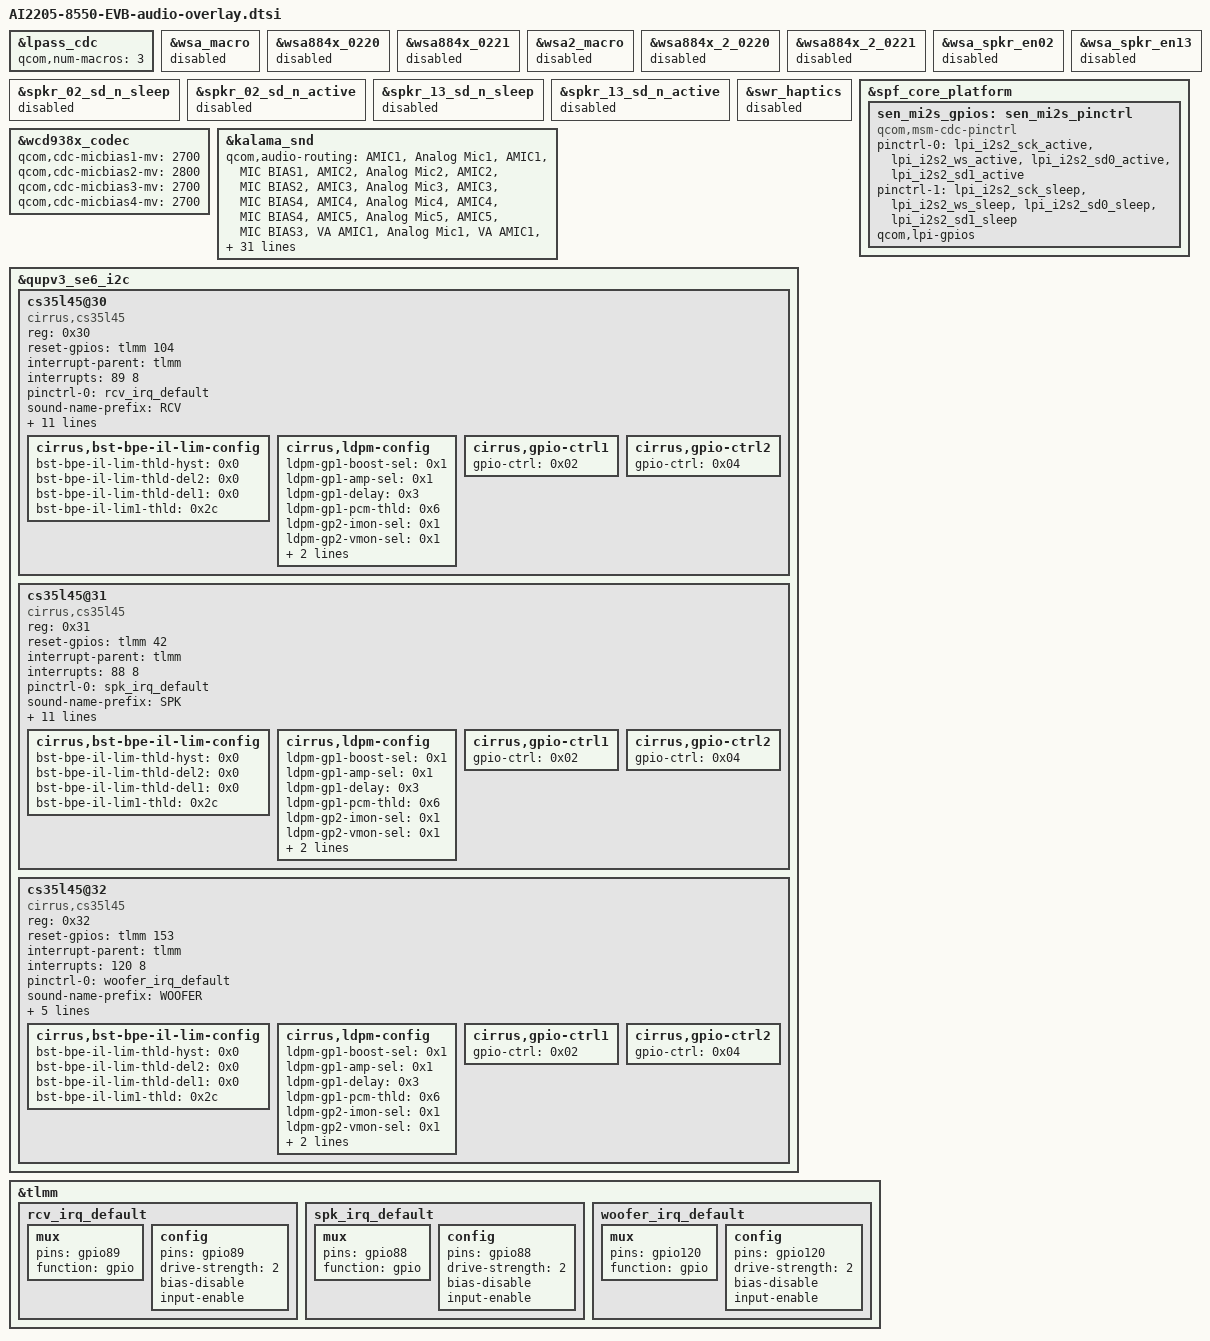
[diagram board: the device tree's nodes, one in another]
#include "kalama-audio-overlay.dtsi"

&lpass_cdc {
	qcom,num-macros = <3>;
};

&wsa_macro {
	status = "disabled";
};

&wsa884x_0220 {
	status = "disabled";
};

&wsa884x_0221 {
	status = "disabled";
};

&wsa2_macro {
	status = "disabled";
};

&wsa884x_2_0220 {
	status = "disabled";
};

&wsa884x_2_0221 {
	status = "disabled";
};

&wsa_spkr_en02 {
	status = "disabled";
};

&wsa_spkr_en13 {
	status = "disabled";
};

&spkr_02_sd_n_sleep {
	status = "disabled";
};

&spkr_02_sd_n_active {
	status = "disabled";
};

&spkr_13_sd_n_sleep {
	status = "disabled";
};

&spkr_13_sd_n_active {
	status = "disabled";
};

&swr_haptics {
	status = "disabled";
};

&spf_core_platform {
	sen_mi2s_gpios: sen_mi2s_pinctrl {
		compatible = "qcom,msm-cdc-pinctrl";
		pinctrl-names = "aud_active", "aud_sleep";
		pinctrl-0 = <&lpi_i2s2_sck_active &lpi_i2s2_ws_active
				&lpi_i2s2_sd0_active &lpi_i2s2_sd1_active>;
		pinctrl-1 = <&lpi_i2s2_sck_sleep &lpi_i2s2_ws_sleep
				&lpi_i2s2_sd0_sleep &lpi_i2s2_sd1_sleep>;
		qcom,lpi-gpios;
		#gpio-cells = <0>;
	};
};

&sen_mi2s_gpios {
	status = "ok";
};

&wcd938x_codec {
	qcom,cdc-micbias1-mv = <2700>;
	qcom,cdc-micbias2-mv = <2800>;
	qcom,cdc-micbias3-mv = <2700>;
	qcom,cdc-micbias4-mv = <2700>;
};

&kalama_snd {
	qcom,audio-routing =
		"AMIC1", "Analog Mic1",
		"AMIC1", "MIC BIAS1",
		"AMIC2", "Analog Mic2",
		"AMIC2", "MIC BIAS2",
		"AMIC3", "Analog Mic3",
		"AMIC3", "MIC BIAS4",
		"AMIC4", "Analog Mic4",
		"AMIC4", "MIC BIAS4",
		"AMIC5", "Analog Mic5",
		"AMIC5", "MIC BIAS3",
		"VA AMIC1", "Analog Mic1",
		"VA AMIC1", "VA MIC BIAS1",
		"VA AMIC2", "Analog Mic2",
		"VA AMIC2", "VA MIC BIAS2",
		"VA AMIC3", "Analog Mic3",
		"VA AMIC3", "VA MIC BIAS3",
		"VA AMIC4", "Analog Mic4",
		"VA AMIC4", "VA MIC BIAS3",
		"VA AMIC5", "Analog Mic5",
		"VA AMIC5", "VA MIC BIAS4",
		"TX DMIC0", "Digital Mic0",
		"TX DMIC0", "MIC BIAS3",
		"TX DMIC1", "Digital Mic1",
		"TX DMIC1", "MIC BIAS3",
		"TX DMIC2", "Digital Mic2",
		"TX DMIC2", "MIC BIAS1",
		"TX DMIC3", "Digital Mic3",
		"TX DMIC3", "MIC BIAS1",
		"IN1_HPHL", "HPHL_OUT",
		"IN2_HPHR", "HPHR_OUT",
		"IN3_AUX", "AUX_OUT",
		"RX_TX DEC0_INP", "TX DEC0 MUX",
		"RX_TX DEC1_INP", "TX DEC1 MUX",
		"RX_TX DEC2_INP", "TX DEC2 MUX",
		"RX_TX DEC3_INP", "TX DEC3 MUX",
		"TX SWR_INPUT", "WCD_TX_OUTPUT",
		"VA SWR_INPUT", "VA_SWR_CLK",
		"VA SWR_INPUT", "WCD_TX_OUTPUT",
		"VA_AIF1 CAP", "VA_SWR_CLK",
		"VA_AIF2 CAP", "VA_SWR_CLK",
		"VA_AIF3 CAP", "VA_SWR_CLK",
		"VA DMIC0", "Digital Mic0",
		"VA DMIC1", "Digital Mic1",
		"VA DMIC2", "Digital Mic2",
		"VA DMIC3", "Digital Mic3",
		"VA DMIC0", "VA MIC BIAS3",
		"VA DMIC1", "VA MIC BIAS3",
		"VA DMIC2", "VA MIC BIAS1",
		"VA DMIC3", "VA MIC BIAS1";

	asoc-codec  = <&stub_codec>, <&lpass_cdc>,
		      <&wcd938x_codec>;
	asoc-codec-names = "msm-stub-codec.1", "lpass-cdc",
			   "wcd938x_codec";
	qcom,wsa-max-devs = <0>;

	qcom,mi2s-audio-intf = <1>;
	qcom,sen-mi2s-gpios = <&sen_mi2s_gpios>;
};

&qupv3_se6_i2c {
	status = "ok";

	cs35l45@30 {
		status = "ok";
		compatible = "cirrus,cs35l45";
		reg = <0x30>;
		reset-gpios = <&tlmm 104 0>;
		interrupt-parent = <&tlmm>;
		interrupts = <89 8>;
		pinctrl-names = "default";
		pinctrl-0 = <&rcv_irq_default>;

		sound-name-prefix = "RCV";
		cirrus,dsp-part-name = "cs35l45-rcv";
		cirrus,fast-switch = "cs35l45-rcv-music.txt",
					"cs35l45-rcv-heavy.txt",
					"cs35l45-rcv-outdoor.txt",
					"cs35l45-rcv-voice.txt",
					"cs35l45-rcv-interim-woofer.txt",
					"cs35l45-rcv-music_woofer_2p1.txt",
					"cs35l45-rcv-heavy_woofer_2p1.txt",
					"cs35l45-rcv-outdoor_woofer_2p1.txt",
					"cs35l45-rcv-voice_woofer_2p1.txt";

		cirrus,asp-sdout-hiz-ctrl = <0x3>;
		cirrus,bst-bpe-il-lim-config {
			bst-bpe-il-lim-thld-hyst = <0x0>;
			bst-bpe-il-lim-thld-del2 = <0x0>;
			bst-bpe-il-lim-thld-del1 = <0x0>;
			bst-bpe-il-lim1-thld = <0x2c>;
		};
		cirrus,ldpm-config {
			ldpm-gp1-boost-sel = <0x1>;
			ldpm-gp1-amp-sel = <0x1>;
			ldpm-gp1-delay = <0x3>;
			ldpm-gp1-pcm-thld = <0x6>;
			ldpm-gp2-imon-sel = <0x1>;
			ldpm-gp2-vmon-sel = <0x1>;
			ldpm-gp2-delay = <0x3>;
			ldpm-gp2-pcm-thld = <0x6>;
		};
		cirrus,gpio-ctrl1 {
			gpio-ctrl = <0x02>;
		};
		cirrus,gpio-ctrl2 {
			gpio-ctrl = <0x04>;
		};
	};

	cs35l45@31 {
		status = "ok";
		compatible = "cirrus,cs35l45";
		reg = <0x31>;
		reset-gpios = <&tlmm 42 0>;
		interrupt-parent = <&tlmm>;
		interrupts = <88 8>;
		pinctrl-names = "default";
		pinctrl-0 = <&spk_irq_default>;

		sound-name-prefix = "SPK";
		cirrus,dsp-part-name = "cs35l45-spk";
		cirrus,fast-switch = "cs35l45-spk-music.txt",
					"cs35l45-spk-heavy.txt",
					"cs35l45-spk-outdoor.txt",
					"cs35l45-spk-voice.txt",
					"cs35l45-spk-interim-woofer.txt",
					"cs35l45-spk-music_woofer_2p1.txt",
					"cs35l45-spk-heavy_woofer_2p1.txt",
					"cs35l45-spk-outdoor_woofer_2p1.txt",
					"cs35l45-spk-voice_woofer_2p1.txt";

		cirrus,asp-sdout-hiz-ctrl = <0x3>;
		cirrus,bst-bpe-il-lim-config {
			bst-bpe-il-lim-thld-hyst = <0x0>;
			bst-bpe-il-lim-thld-del2 = <0x0>;
			bst-bpe-il-lim-thld-del1 = <0x0>;
			bst-bpe-il-lim1-thld = <0x2c>;
		};
		cirrus,ldpm-config {
			ldpm-gp1-boost-sel = <0x1>;
			ldpm-gp1-amp-sel = <0x1>;
			ldpm-gp1-delay = <0x3>;
			ldpm-gp1-pcm-thld = <0x6>;
			ldpm-gp2-imon-sel = <0x1>;
			ldpm-gp2-vmon-sel = <0x1>;
			ldpm-gp2-delay = <0x3>;
			ldpm-gp2-pcm-thld = <0x6>;
		};
		cirrus,gpio-ctrl1 {
			gpio-ctrl = <0x02>;
		};
		cirrus,gpio-ctrl2 {
			gpio-ctrl = <0x04>;
		};
	};

	cs35l45@32 {
		status = "ok";
		compatible = "cirrus,cs35l45";
		reg = <0x32>;
		reset-gpios = <&tlmm 153 0>;
		interrupt-parent = <&tlmm>;
		interrupts = <120 8>;
		pinctrl-names = "default";
		pinctrl-0 = <&woofer_irq_default>;

		sound-name-prefix = "WOOFER";
		cirrus,dsp-part-name = "cs35l45-woofer";
		cirrus,fast-switch = "cs35l45-woofer-music.txt", "cs35l45-woofer-heavy.txt", "cs35l45-woofer-outdoor.txt";

		cirrus,asp-sdout-hiz-ctrl = <0x3>;
		cirrus,bst-bpe-il-lim-config {
			bst-bpe-il-lim-thld-hyst = <0x0>;
			bst-bpe-il-lim-thld-del2 = <0x0>;
			bst-bpe-il-lim-thld-del1 = <0x0>;
			bst-bpe-il-lim1-thld = <0x2c>;
		};
		cirrus,ldpm-config {
			ldpm-gp1-boost-sel = <0x1>;
			ldpm-gp1-amp-sel = <0x1>;
			ldpm-gp1-delay = <0x3>;
			ldpm-gp1-pcm-thld = <0x6>;
			ldpm-gp2-imon-sel = <0x1>;
			ldpm-gp2-vmon-sel = <0x1>;
			ldpm-gp2-delay = <0x3>;
			ldpm-gp2-pcm-thld = <0x6>;
		};
		cirrus,gpio-ctrl1 {
			gpio-ctrl = <0x02>;
		};
		cirrus,gpio-ctrl2 {
			gpio-ctrl = <0x04>;
		};
	};
};

&tlmm {
	rcv_irq_default: rcv_irq_default {
		mux {
			pins = "gpio89";
			function = "gpio";
		};

		config {
			pins = "gpio89";
			drive-strength = <2>;
			bias-disable;           /* NO PULL */
			input-enable;
		};
	};

	spk_irq_default: spk_irq_default {
		mux {
			pins = "gpio88";
			function = "gpio";
		};

		config {
			pins = "gpio88";
			drive-strength = <2>;
			bias-disable;           /* NO PULL */
			input-enable;
		};
	};

	woofer_irq_default: woofer_irq_default {
		mux {
			pins = "gpio120";
			function = "gpio";
		};

		config {
			pins = "gpio120";
			drive-strength = <2>;
			bias-disable;           /* NO PULL */
			input-enable;
		};
	};
};

&rcv_irq_default {
	status = "ok";
};

&spk_irq_default {
	status = "ok";
};

&woofer_irq_default {
	status = "ok";
};

